# GD32M53x register map
File version: 1.0
CPU: CM33 r2p1, little endian, MPU, FPU, DSP, 4 interrupt priority bits
Registers are 32-bit, read-write, reset 0x0 unless marked. A register's access mark holds for its fields unless they carry their own. Offsets are from the block's base; [hi:lo] are bit positions; {n}, {i} and the like mark numbered series; 'fields as' and 'values as' point back to an identical list.

## GTOC — GPTIMER Output Controller
Base 0x48004800
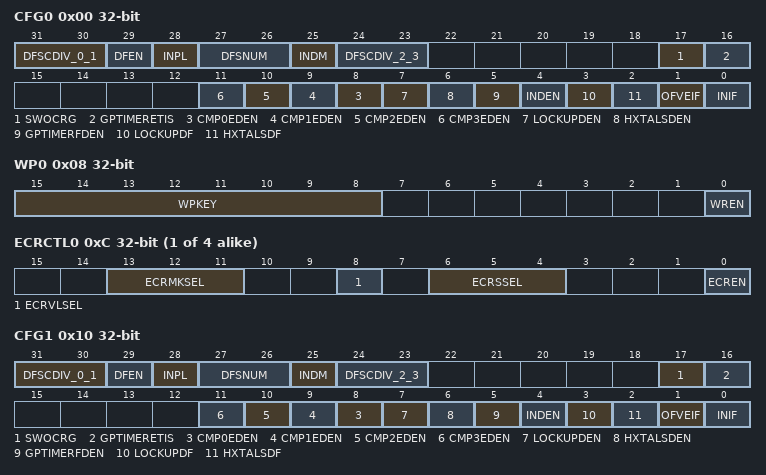
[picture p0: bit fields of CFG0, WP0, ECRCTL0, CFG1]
0x00 CFG0 access per field — Configuration Register 0
  [31:30] DFSCDIV_0_1 rw — GTOCx digital filter sampling clock division
  [29] DFEN rw — GTOCx digital filter enable
  [28] INPL rw — Polarity of GTOCx_IN input
  [27:26] DFSNUM rw — GTOCx digital filter sampling number
  [25] INDM rw — GTOCx_IN input detection mode
  [24:23] DFSCDIV_2_3 rw — Refer to DFSCDIV[1:0] bits.
  [17] SWOCRG rw — Software output closing request generation
  [16] GPTIMERETIS ro — GPTIMER external trigger input x status
  [n+8] CMP{n}EDEN rw (n=0..3) — CMP{n} valid edge detection enable
  [7] LOCKUPDEN rw — CPU LOCKUP detection enable
  [6] HXTALSDEN rw — HXTAL stuck detection enable
  [5] GPTIMERFDEN rw — GPTIMER output fault detection enable
  [4] INDEN rw — GTOCx_IN input detection enable
  [3] LOCKUPDF rw — CPU LOCKUP detection flag
  [2] HXTALSDF rw — HXTAL stuck detection flag
  [1] OFVEIF rw — GPTIMER output fault or CMP valid edge interrupt flag
  [0] INIF rw — GTOCx_IN input interrupt flag
{0x4+0x10*i} OCRCTL{i} (i=0..3) — GTOC{i} output closing request control regist {i}
  [2:0] OCRMKSEL — Output closing request mask source selection
0x08 WP0 access per field — GTOCx write protection regist 0
  [15:8] WPKEY wo — Write protect key
  [0] WREN rw — GTOCx_ECRCTL register write enable.
{0xC+0x10*i} ECRCTL{i} (i=0..3) — GTOC{i} extended closing request control regist {i}
  [13:11] ECRMKSEL — Extended closing request mask source selection
  [8] ECRVLSEL — Extended closing request valid level selection
  [6:4] ECRSSEL — Extended closing request source selection
  [0] ECREN — Extended closing request enable
0x10 CFG1 access per field — GTOC1 configuration regist 1
  [31:30] DFSCDIV_0_1 rw — GTOCx digital filter sampling clock division
  [29] DFEN rw — GTOCx digital filter enable
  [28] INPL rw — Polarity of GTOCx_IN input
  [27:26] DFSNUM rw — GTOCx digital filter sampling number
  [25] INDM rw — GTOCx_IN input detection mode
  [24:23] DFSCDIV_2_3 rw — GTOC digital filter sampling clock division.
  [17] SWOCRG rw — Software output closing request generation
  [16] GPTIMERETIS ro — GPTIMER external trigger input x status
  [n+8] CMP{n}EDEN rw (n=0..3) — CMP{n} valid edge detection enable
  [7] LOCKUPDEN rw — CPU LOCKUP detection enable
  [6] HXTALSDEN rw — HXTAL stuck detection enable
  [5] GPTIMERFDEN rw — GPTIMER output fault detection enable
  [4] INDEN rw — GTOCx_IN input detection enable
  [3] LOCKUPDF rw — CPU LOCKUP detection flag
  [2] HXTALSDF rw — HXTAL stuck detection flag
  [1] OFVEIF rw — GPTIMER output fault or CMP valid edge interrupt flag
  [0] INIF rw — GTOCx_IN input interrupt flag
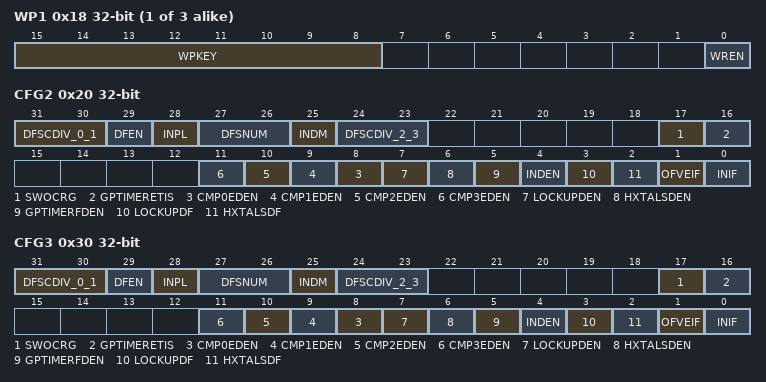
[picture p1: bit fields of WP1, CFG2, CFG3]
{0x8+0x10*i} WP{i} access per field (i=1..3) — GTOC{i} write protection regist {i}
  fields as WP0
0x20 CFG2 access per field — GTOC2 configuration regist 2
  fields as CFG0
0x30 CFG3 access per field — GTOC3 configuration regist 3
  fields as CFG0

## PMU — Power management unit
Base 0x40007000
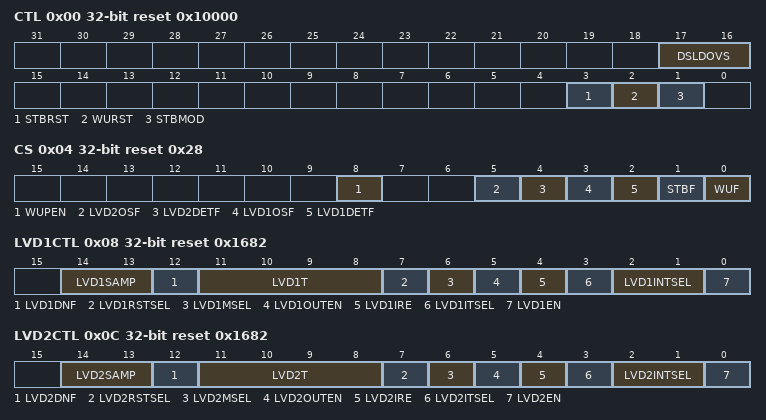
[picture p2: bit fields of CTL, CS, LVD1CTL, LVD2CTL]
0x00 CTL reset 0x10000 — Control register
  [17:16] DSLDOVS — Deep-sleep mode voltage scaling selection
  [3] STBRST — Standby flag reset
  [2] WURST — Wakeup flag reset
  [1] STBMOD — Standby mode
0x04 CS access per field reset 0x28 — Control and status register
  [8] WUPEN rw — WKUP pin enable
  [5] LVD2OSF ro — Low voltage detector 2 output signal flag
  [4] LVD2DETF ro — Low voltage detector 2 voltage change detection flag
  [3] LVD1OSF ro — Low voltage detector 1 output signal flag
  [2] LVD1DETF ro — Low voltage detector 1 voltage change detection flag
  [1] STBF ro — Standby flag
  [0] WUF ro — Wakeup flag
0x08 LVD1CTL reset 0x1682 — Low Voltage Detector 1 Control Register
  [14:13] LVD1SAMP — Sampling clock select
  [12] LVD1DNF — Low voltage detector 1 digital noise filter enable
  [11:8] LVD1T — Low voltage detector 1 threshold
  [7] LVD1RSTSEL — Low voltage detector 1 reset signal negation selection
  [6] LVD1MSEL — Low voltage detector 1 Mode Selection
  [5] LVD1OUTEN — Low voltage detector 1 comparison result output enable
  [4] LVD1IRE — Low voltage detector 1 Interrupt / Reset Enable
  [3] LVD1ITSEL — Low voltage detector 1 Interrupt Type Select
  [2:1] LVD1INTSEL — Low voltage detector 1 interrupt trigger mode
  [0] LVD1EN — Low voltage detector 1 Enable
0x0C LVD2CTL reset 0x1682 — Low Voltage Detector 2 Control Register
  [14:13] LVD2SAMP — Sampling clock select
  [12] LVD2DNF — Low voltage detector 2 digital noise filter enable
  [11:8] LVD2T — Low voltage detector 2 threshold
  [7] LVD2RSTSEL — Low voltage detector 2 reset signal negation selection
  [6] LVD2MSEL — Low voltage detector 2 Mode Selection
  [5] LVD2OUTEN — Low voltage detector 2 comparison result output enabled
  [4] LVD2IRE — Low voltage detector 2 Interrupt / Reset enable
  [3] LVD2ITSEL — Low voltage detector 2 Interrupt Type Selection
  [2:1] LVD2INTSEL — Low voltage detector 2 interrupt trigger mode
  [0] LVD2EN — Low voltage detector 2 enable
